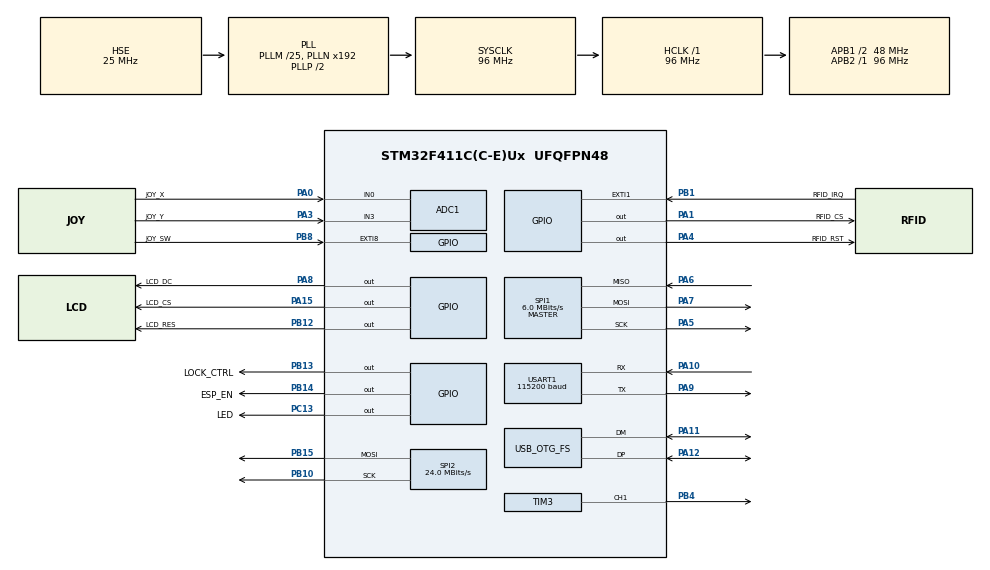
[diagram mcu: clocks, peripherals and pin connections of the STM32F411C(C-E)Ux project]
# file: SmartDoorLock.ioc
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ADC1.Channel-0\#ChannelRegularConversion=ADC_CHANNEL_0
ADC1.NbrOfConversionFlag=1
ADC1.Rank-0\#ChannelRegularConversion=1
ADC1.SamplingTime-0\#ChannelRegularConversion=ADC_SAMPLETIME_84CYCLES
ADC1.master=1
Dma.Request0=SPI2_TX
Dma.Request1=USART1_RX
Dma.Request2=USART1_TX
Dma.SPI2_TX.0.Direction=DMA_MEMORY_TO_PERIPH
Dma.SPI2_TX.0.FIFOMode=DMA_FIFOMODE_DISABLE
Dma.SPI2_TX.0.Instance=DMA1_Stream4
Dma.SPI2_TX.0.MemDataAlignment=DMA_MDATAALIGN_BYTE
Dma.SPI2_TX.0.MemInc=DMA_MINC_ENABLE
Dma.SPI2_TX.0.Mode=DMA_NORMAL
Dma.SPI2_TX.0.PeriphDataAlignment=DMA_PDATAALIGN_BYTE
Dma.SPI2_TX.0.PeriphInc=DMA_PINC_DISABLE
Dma.SPI2_TX.0.Priority=DMA_PRIORITY_MEDIUM
Dma.USART1_RX.1.Direction=DMA_PERIPH_TO_MEMORY
Dma.USART1_RX.1.FIFOMode=DMA_FIFOMODE_DISABLE
Dma.USART1_RX.1.Instance=DMA2_Stream2
Dma.USART1_RX.1.MemDataAlignment=DMA_MDATAALIGN_BYTE
Dma.USART1_RX.1.MemInc=DMA_MINC_ENABLE
Dma.USART1_RX.1.Mode=DMA_CIRCULAR
Dma.USART1_RX.1.PeriphDataAlignment=DMA_PDATAALIGN_BYTE
Dma.USART1_RX.1.PeriphInc=DMA_PINC_DISABLE
Dma.USART1_RX.1.Priority=DMA_PRIORITY_LOW
Dma.USART1_TX.2.Direction=DMA_MEMORY_TO_PERIPH
Dma.USART1_TX.2.FIFOMode=DMA_FIFOMODE_DISABLE
Dma.USART1_TX.2.Instance=DMA2_Stream7
Dma.USART1_TX.2.MemDataAlignment=DMA_MDATAALIGN_BYTE
Dma.USART1_TX.2.MemInc=DMA_MINC_ENABLE
Dma.USART1_TX.2.Mode=DMA_NORMAL
Dma.USART1_TX.2.PeriphDataAlignment=DMA_PDATAALIGN_BYTE
Dma.USART1_TX.2.PeriphInc=DMA_PINC_DISABLE
Dma.USART1_TX.2.Priority=DMA_PRIORITY_LOW
FREERTOS.INCLUDE_uxTaskGetStackHighWaterMark=1
FREERTOS.Tasks01=defaultTask,24,256,StartDefaultTask,Default,NULL,Dynamic,NULL,NULL
FREERTOS.configCHECK_FOR_STACK_OVERFLOW=2
FREERTOS.configRECORD_STACK_HIGH_ADDRESS=1
FREERTOS.configTOTAL_HEAP_SIZE=32768
FREERTOS.configUSE_MALLOC_FAILED_HOOK=1
FREERTOS.configUSE_MUTEXES=1
FREERTOS.configUSE_NEWLIB_REENTRANT=1
FREERTOS.configUSE_TIMERS=1
IWDG.Prescaler=IWDG_PRESCALER_128
IWDG.Reload=1000
Mcu.Family=STM32F4
Mcu.Name=STM32F411C(C-E)Ux
Mcu.Package=UFQFPN48
NVIC.DMA1_Stream4_IRQn=true\:5\:0\:false\:false\:true\:true\:false\:true\:true
NVIC.DMA2_Stream2_IRQn=true\:5\:0\:false\:false\:true\:true\:false\:true\:true
NVIC.DMA2_Stream7_IRQn=true\:5\:0\:false\:false\:true\:true\:false\:true\:true
NVIC.EXTI9_5_IRQn=true\:5\:0\:false\:false\:true\:true\:true\:true\:true
NVIC.OTG_FS_IRQn=true\:5\:0\:false\:false\:true\:false\:true\:true\:true
NVIC.PriorityGroup=NVIC_PRIORITYGROUP_4
NVIC.SPI2_IRQn=true\:5\:0\:false\:false\:true\:true\:true\:true\:true
NVIC.TIM1_TRG_COM_TIM11_IRQn=true\:15\:0\:false\:false\:true\:false\:false\:true\:true
NVIC.TimeBase=TIM1_TRG_COM_TIM11_IRQn
NVIC.TimeBaseIP=TIM11
NVIC.USART1_IRQn=true\:5\:0\:false\:false\:true\:true\:true\:true\:true
PA0-WKUP.GPIO_Label=JOY_X
PA0-WKUP.Signal=ADCx_IN0
PA1.GPIO_Label=RFID_CS
PA1.GPIO_Speed=GPIO_SPEED_FREQ_HIGH
PA1.PinState=GPIO_PIN_SET
PA1.Signal=GPIO_Output
PA10.Mode=Asynchronous
PA10.Signal=USART1_RX
PA11.Mode=Device_Only
PA11.Signal=USB_OTG_FS_DM
PA12.Mode=Device_Only
PA12.Signal=USB_OTG_FS_DP
PA13.Mode=Serial_Wire
PA13.Signal=SYS_JTMS-SWDIO
PA14.Mode=Serial_Wire
PA14.Signal=SYS_JTCK-SWCLK
PA15.GPIO_Label=LCD_CS
PA15.GPIO_Speed=GPIO_SPEED_FREQ_HIGH
PA15.PinState=GPIO_PIN_SET
PA15.Signal=GPIO_Output
PA3.GPIO_Label=JOY_Y
PA3.Signal=ADCx_IN3
PA4.GPIO_Label=RFID_RST
PA4.PinState=GPIO_PIN_SET
PA4.Signal=GPIO_Output
PA5.Mode=Full_Duplex_Master
PA5.Signal=SPI1_SCK
PA6.Mode=Full_Duplex_Master
PA6.Signal=SPI1_MISO
PA7.Mode=Full_Duplex_Master
PA7.Signal=SPI1_MOSI
PA8.GPIO_Label=LCD_DC
PA8.GPIO_Speed=GPIO_SPEED_FREQ_HIGH
PA8.Signal=GPIO_Output
PA9.Mode=Asynchronous
PA9.Signal=USART1_TX
PB1.GPIO_Label=RFID_IRQ
PB1.GPIO_ModeDefaultEXTI=GPIO_MODE_IT_FALLING
PB1.GPIO_PuPd=GPIO_PULLUP
PB1.Signal=GPXTI1
PB10.Mode=TX_Only_Simplex_Unidirect_Master
PB10.Signal=SPI2_SCK
PB12.GPIO_Label=LCD_RES
PB12.PinState=GPIO_PIN_SET
PB12.Signal=GPIO_Output
PB13.GPIO_Label=LOCK_CTRL
PB13.GPIO_PuPd=GPIO_PULLDOWN
PB13.Signal=GPIO_Output
PB14.GPIO_Label=ESP_EN
PB14.Signal=GPIO_Output
PB15.Mode=TX_Only_Simplex_Unidirect_Master
PB15.Signal=SPI2_MOSI
PB4.Signal=S_TIM3_CH1
PB8.GPIO_Label=JOY_SW
PB8.GPIO_ModeDefaultEXTI=GPIO_MODE_IT_FALLING
PB8.GPIO_PuPd=GPIO_PULLUP
PB8.Signal=GPXTI8
PC13-ANTI_TAMP.GPIO_Label=LED
PC13-ANTI_TAMP.PinState=GPIO_PIN_SET
PC13-ANTI_TAMP.Signal=GPIO_Output
PH0\ -\ OSC_IN.Mode=HSE-External-Oscillator
PH0\ -\ OSC_IN.Signal=RCC_OSC_IN
PH1\ -\ OSC_OUT.Mode=HSE-External-Oscillator
PH1\ -\ OSC_OUT.Signal=RCC_OSC_OUT
ProjectManager.HeapSize=0x200
ProjectManager.StackSize=0x400
ProjectManager.TargetToolchain=STM32CubeIDE
RCC.48MHZClocksFreq_Value=48000000
RCC.AHBFreq_Value=96000000
RCC.APB1CLKDivider=RCC_HCLK_DIV2
RCC.APB1Freq_Value=48000000
RCC.APB1TimFreq_Value=96000000
RCC.APB2Freq_Value=96000000
RCC.APB2TimFreq_Value=96000000
RCC.CortexFreq_Value=96000000
RCC.HCLKFreq_Value=96000000
RCC.HSE_VALUE=25000000
RCC.HSI_VALUE=16000000
RCC.LSE_VALUE=32768
RCC.PLLM=25
RCC.PLLN=192
RCC.PLLQ=4
RCC.SYSCLKFreq_VALUE=96000000
RCC.SYSCLKSource=RCC_SYSCLKSOURCE_PLLCLK
RCC.VCOOutputFreq_Value=192000000
SH.ADCx_IN0.0=ADC1_IN0,IN0
SH.ADCx_IN3.0=ADC1_IN3,IN3
SH.S_TIM3_CH1.0=TIM3_CH1,PWM Generation1 CH1
SPI1.BaudRatePrescaler=SPI_BAUDRATEPRESCALER_16
SPI1.CalculateBaudRate=6.0 MBits/s
SPI1.Direction=SPI_DIRECTION_2LINES
SPI1.Mode=SPI_MODE_MASTER
SPI1.VirtualType=VM_MASTER
SPI2.BaudRatePrescaler=SPI_BAUDRATEPRESCALER_2
SPI2.CalculateBaudRate=24.0 MBits/s
SPI2.Direction=SPI_DIRECTION_2LINES
SPI2.Mode=SPI_MODE_MASTER
SPI2.VirtualType=VM_MASTER
TIM3.AutoReloadPreload=TIM_AUTORELOAD_PRELOAD_ENABLE
TIM3.Channel-PWM\ Generation1\ CH1=TIM_CHANNEL_1
TIM3.Period=499
TIM3.Prescaler=95
TIM3.Pulse-PWM\ Generation1\ CH1=0
USART1.BaudRate=115200
USART1.VirtualMode=VM_ASYNC
USB_DEVICE.CLASS_NAME_FS=CDC
USB_DEVICE.VirtualMode=Cdc
USB_DEVICE.VirtualMode-CDC_FS=Cdc
USB_DEVICE.VirtualModeFS=Cdc_FS
USB_OTG_FS.VirtualMode=Device_Only
VP_FREERTOS_VS_CMSIS_V2.Mode=CMSIS_V2
VP_IWDG_VS_IWDG.Mode=IWDG_Activate
VP_SYS_VS_tim11.Mode=TIM11
VP_TIM3_VS_ClockSourceINT.Mode=Internal
VP_USB_DEVICE_VS_USB_DEVICE_CDC_FS.Mode=CDC_FS
board=custom

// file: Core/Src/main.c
/* USER CODE BEGIN Header */
/**
  ******************************************************************************
  * @file           : main.c
  * @brief          : Main program body
  ******************************************************************************
  * @attention
  *
  * Copyright (c) 2026 STMicroelectronics.
  * All rights reserved.
  *
  * This software is licensed under terms that can be found in the LICENSE file
  * in the root directory of this software component.
  * If no LICENSE file comes with this software, it is provided AS-IS.
  *
  ******************************************************************************
  */
/* USER CODE END Header */
#include "main.h"
#include "cmsis_os.h"
#include "adc.h"
#include "dma.h"
#include "iwdg.h"
#include "spi.h"
#include "tim.h"
#include "usart.h"
#include "usb_device.h"
#include "gpio.h"

void SystemClock_Config(void);
void MX_FREERTOS_Init(void);

int main(void)
{

  /* MCU Configuration--------------------------------------------------------*/

  /* Reset of all peripherals, Initializes the Flash interface and the Systick. */
  HAL_Init();

  /* Configure the system clock */
  SystemClock_Config();

  /* Initialize all configured peripherals */
  MX_GPIO_Init();
  MX_DMA_Init();
  MX_ADC1_Init();
  MX_IWDG_Init();
  MX_SPI1_Init();
  MX_SPI2_Init();
  MX_TIM3_Init();
  MX_USART1_UART_Init();

  /* Init scheduler */
  osKernelInitialize();  /* Call init function for freertos objects (in cmsis_os2.c) */
  MX_FREERTOS_Init();

  /* Start scheduler */
  osKernelStart();

  /* We should never get here as control is now taken by the scheduler */

  /* Infinite loop */
  while (1)
  {

  }
}

void SystemClock_Config(void)
{
  RCC_OscInitTypeDef RCC_OscInitStruct = {0};
  RCC_ClkInitTypeDef RCC_ClkInitStruct = {0};

  /** Configure the main internal regulator output voltage
  */
  __HAL_RCC_PWR_CLK_ENABLE();
  __HAL_PWR_VOLTAGESCALING_CONFIG(PWR_REGULATOR_VOLTAGE_SCALE1);

  /** Initializes the RCC Oscillators according to the specified parameters
  * in the RCC_OscInitTypeDef structure.
  */
  RCC_OscInitStruct.OscillatorType = RCC_OSCILLATORTYPE_LSI|RCC_OSCILLATORTYPE_HSE;
  RCC_OscInitStruct.HSEState = RCC_HSE_ON;
  RCC_OscInitStruct.LSIState = RCC_LSI_ON;
  RCC_OscInitStruct.PLL.PLLState = RCC_PLL_ON;
  RCC_OscInitStruct.PLL.PLLSource = RCC_PLLSOURCE_HSE;
  RCC_OscInitStruct.PLL.PLLM = 25;
  RCC_OscInitStruct.PLL.PLLN = 192;
  RCC_OscInitStruct.PLL.PLLP = RCC_PLLP_DIV2;
  RCC_OscInitStruct.PLL.PLLQ = 4;
  if (HAL_RCC_OscConfig(&RCC_OscInitStruct) != HAL_OK)
  {
    Error_Handler();
  }

  /** Initializes the CPU, AHB and APB buses clocks
  */
  RCC_ClkInitStruct.ClockType = RCC_CLOCKTYPE_HCLK|RCC_CLOCKTYPE_SYSCLK
                              |RCC_CLOCKTYPE_PCLK1|RCC_CLOCKTYPE_PCLK2;
  RCC_ClkInitStruct.SYSCLKSource = RCC_SYSCLKSOURCE_PLLCLK;
  RCC_ClkInitStruct.AHBCLKDivider = RCC_SYSCLK_DIV1;
  RCC_ClkInitStruct.APB1CLKDivider = RCC_HCLK_DIV2;
  RCC_ClkInitStruct.APB2CLKDivider = RCC_HCLK_DIV1;

  if (HAL_RCC_ClockConfig(&RCC_ClkInitStruct, FLASH_LATENCY_3) != HAL_OK)
  {
    Error_Handler();
  }
}

void HAL_TIM_PeriodElapsedCallback(TIM_HandleTypeDef *htim)
{
  if (htim->Instance == TIM11)
  {
    HAL_IncTick();
  }
}

void Error_Handler(void)
{
  __disable_irq();
  while (1)
  {
  }
}

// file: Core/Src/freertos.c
/* USER CODE BEGIN Header */
/**
  ******************************************************************************
  * File Name          : freertos.c
  * Description        : Code for freertos applications
  ******************************************************************************
  * @attention
  *
  * Copyright (c) 2026 STMicroelectronics.
  * All rights reserved.
  *
  * This software is licensed under terms that can be found in the LICENSE file
  * in the root directory of this software component.
  * If no LICENSE file comes with this software, it is provided AS-IS.
  *
  ******************************************************************************
  */
/* USER CODE END Header */

#include "FreeRTOS.h"
#include "task.h"
#include "main.h"
#include "cmsis_os.h"

/* USER CODE BEGIN Includes */
#include "app.h"
#include "supervisor.h"
/* USER CODE END Includes */

/* Definitions for defaultTask */
osThreadId_t defaultTaskHandle;
const osThreadAttr_t defaultTask_attributes = {
  .name = "defaultTask",
  .stack_size = 256 * 4,
  .priority = (osPriority_t) osPriorityNormal,
};

void StartDefaultTask(void *argument);

extern void MX_USB_DEVICE_Init(void);
void MX_FREERTOS_Init(void); /* (MISRA C 2004 rule 8.1) */

/* Hook prototypes */
void vApplicationStackOverflowHook(xTaskHandle xTask, signed char *pcTaskName);
void vApplicationMallocFailedHook(void);

/* USER CODE BEGIN 4 */
void vApplicationStackOverflowHook(xTaskHandle xTask, signed char *pcTaskName)
{
  (void)xTask;
  SUP_FatalReset(RESET_REASON_STACK_OVERFLOW, (const char *)pcTaskName);
}
/* USER CODE END 4 */

/* USER CODE BEGIN 5 */
void vApplicationMallocFailedHook(void)
{
  SUP_FatalReset(RESET_REASON_MALLOC_FAILED, NULL);
}
/* USER CODE END 5 */

void MX_FREERTOS_Init(void) {

  /* Create the thread(s) */
  /* creation of defaultTask */
  defaultTaskHandle = osThreadNew(StartDefaultTask, NULL, &defaultTask_attributes);

  /* USER CODE BEGIN RTOS_THREADS */
  App_CreateRtosObjects();
  /* USER CODE END RTOS_THREADS */

}

void StartDefaultTask(void *argument)
{
  /* init code for USB_DEVICE */
  MX_USB_DEVICE_Init();
  /* USER CODE BEGIN StartDefaultTask */
  /* Only brings up USB (generated call above); tLog owns it from here. */
  osThreadExit();
  /* USER CODE END StartDefaultTask */
}
